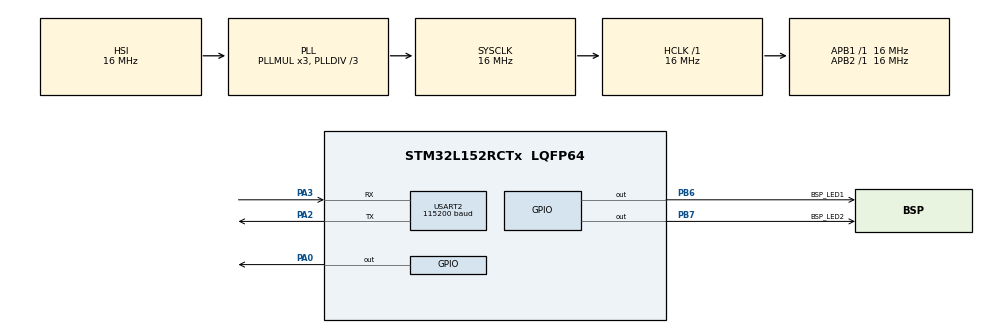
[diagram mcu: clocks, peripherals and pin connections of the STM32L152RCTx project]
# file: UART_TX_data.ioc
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Dma.Request0=USART2_TX
Dma.Request1=USART2_RX
Dma.USART2_RX.1.Direction=DMA_PERIPH_TO_MEMORY
Dma.USART2_RX.1.Instance=DMA1_Channel6
Dma.USART2_RX.1.MemDataAlignment=DMA_MDATAALIGN_BYTE
Dma.USART2_RX.1.MemInc=DMA_MINC_ENABLE
Dma.USART2_RX.1.Mode=DMA_NORMAL
Dma.USART2_RX.1.PeriphDataAlignment=DMA_PDATAALIGN_BYTE
Dma.USART2_RX.1.PeriphInc=DMA_PINC_DISABLE
Dma.USART2_RX.1.Priority=DMA_PRIORITY_LOW
Dma.USART2_TX.0.Direction=DMA_MEMORY_TO_PERIPH
Dma.USART2_TX.0.Instance=DMA1_Channel7
Dma.USART2_TX.0.MemDataAlignment=DMA_MDATAALIGN_BYTE
Dma.USART2_TX.0.MemInc=DMA_MINC_ENABLE
Dma.USART2_TX.0.Mode=DMA_CIRCULAR
Dma.USART2_TX.0.PeriphDataAlignment=DMA_PDATAALIGN_BYTE
Dma.USART2_TX.0.PeriphInc=DMA_PINC_DISABLE
Dma.USART2_TX.0.Priority=DMA_PRIORITY_LOW
Mcu.Family=STM32L1
Mcu.Name=STM32L152RCTx
Mcu.Package=LQFP64
NVIC.DMA1_Channel6_IRQn=true\:0\:0\:false\:false\:true\:false\:true\:true
NVIC.DMA1_Channel7_IRQn=true\:0\:0\:false\:false\:true\:false\:true\:true
NVIC.PriorityGroup=NVIC_PRIORITYGROUP_0
NVIC.USART2_IRQn=true\:0\:0\:false\:false\:true\:true\:true\:true
PA0-WKUP1.Signal=GPIO_Output
PA2.Mode=Asynchronous
PA2.Signal=USART2_TX
PA3.Mode=Asynchronous
PA3.Signal=USART2_RX
PB6.GPIO_Label=BSP_LED1
PB6.Signal=GPIO_Output
PB7.GPIO_Label=BSP_LED2
PB7.Signal=GPIO_Output
PH0-OSC_IN.Mode=HSE-External-Oscillator
PH0-OSC_IN.Signal=RCC_OSC_IN
PH1-OSC_OUT.Mode=HSE-External-Oscillator
PH1-OSC_OUT.Signal=RCC_OSC_OUT
ProjectManager.HeapSize=0x200
ProjectManager.StackSize=0x400
ProjectManager.TargetToolchain=STM32CubeIDE
RCC.48MHZClocksFreq_Value=24000000
RCC.AHBFreq_Value=16000000
RCC.APB1Freq_Value=16000000
RCC.APB1TimFreq_Value=16000000
RCC.APB2Freq_Value=16000000
RCC.APB2TimFreq_Value=16000000
RCC.HCLKFreq_Value=16000000
RCC.HSE_VALUE=8000000
RCC.HSI_VALUE=16000000
RCC.LSE_VALUE=32768
RCC.MSI_VALUE=2097000
RCC.PLLDIV=RCC_PLL_DIV3
RCC.RTCClockSelectionVirtual=RCC_RTCCLKSOURCE_LSE
RCC.SYSCLKFreq_VALUE=16000000
RCC.SYSCLKSource=RCC_SYSCLKSOURCE_PLLCLK
RCC.USBOutput=48000000
RCC.VCOOutputFreq_Value=48000000
USART2.BaudRate=115200
USART2.VirtualMode=VM_ASYNC
board=STM32L152C-DISCO

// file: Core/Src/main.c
/* USER CODE BEGIN Header */
/**
 ******************************************************************************
 * @file           : main.c
 * @brief          : Main program body
 ******************************************************************************
 * @attention
 *
 * Copyright (c) 2023 STMicroelectronics.
 * All rights reserved.
 *
 * This software is licensed under terms that can be found in the LICENSE file
 * in the root directory of this software component.
 * If no LICENSE file comes with this software, it is provided AS-IS.
 *
 ******************************************************************************
 */
/* USER CODE END Header */
#include "main.h"

UART_HandleTypeDef huart2;
DMA_HandleTypeDef hdma_usart2_tx;
DMA_HandleTypeDef hdma_usart2_rx;

void SystemClock_Config(void);
static void MX_GPIO_Init(void);
static void MX_DMA_Init(void);
static void MX_USART2_UART_Init(void);
/* USER CODE BEGIN PFP */
unsigned char data[] = "HIREnjadav\n\r";
unsigned char rx_data[20];

//void HAL_UART_TxHalfCpltCallback(UART_HandleTypeDef *huart) {
//	HAL_GPIO_TogglePin(BSP_LED1_GPIO_Port, BSP_LED1_Pin);
//
//}
//
//void HAL_UART_TxCpltCallback(UART_HandleTypeDef *huart) {
//	HAL_UART_Transmit_DMA(&huart2, data, 5);
//
//}

//void HAL_UART_RxCpltCallback(UART_HandleTypeDef *huart)
//{
//	HAL_UART_Receive_IT(&huart2, rx_data, 10);
//
//}
/* USER CODE END PFP */

int main(void) {

	/* MCU Configuration--------------------------------------------------------*/

	/* Reset of all peripherals, Initializes the Flash interface and the Systick. */
	HAL_Init();

	/* Configure the system clock */
	SystemClock_Config();

	/* Initialize all configured peripherals */
	MX_GPIO_Init();
	MX_DMA_Init();
	MX_USART2_UART_Init();
	/* USER CODE BEGIN 2 */

//HAL_UART_Receive_IT(&huart2, rx_data, 10);
//HAL_UART_Transmit_IT(&huart2, data, 5);
//HAL_UART_Receive_DMA(&huart2, rx_data, 5);
//	HAL_UART_Transmit_DMA(&huart2, data, 5);
	/* USER CODE END 2 */

	/* Infinite loop */
	while (1) {

		/* USER CODE BEGIN 3 */

		HAL_UART_Transmit(&huart2, data, 10, 1000);// poll method transmit data
//		HAL_Delay(500);

//
//		if (HAL_UART_Receive(&huart2, rx_data, 10, 1000) == HAL_OK) //read the data  poll method
//				{
//			HAL_GPIO_TogglePin(BSP_LED1_GPIO_Port, BSP_LED1_Pin);
//			HAL_UART_Transmit(&huart2, rx_data, 10, 1000);
//		}

	}
	/* USER CODE END 3 */
}

void SystemClock_Config(void) {
	RCC_OscInitTypeDef RCC_OscInitStruct = { 0 };
	RCC_ClkInitTypeDef RCC_ClkInitStruct = { 0 };

	/** Configure the main internal regulator output voltage
	 */
	__HAL_PWR_VOLTAGESCALING_CONFIG(PWR_REGULATOR_VOLTAGE_SCALE1);

	/** Initializes the RCC Oscillators according to the specified parameters
	 * in the RCC_OscInitTypeDef structure.
	 */
	RCC_OscInitStruct.OscillatorType = RCC_OSCILLATORTYPE_HSI;
	RCC_OscInitStruct.HSIState = RCC_HSI_ON;
	RCC_OscInitStruct.HSICalibrationValue = RCC_HSICALIBRATION_DEFAULT;
	RCC_OscInitStruct.PLL.PLLState = RCC_PLL_ON;
	RCC_OscInitStruct.PLL.PLLSource = RCC_PLLSOURCE_HSI;
	RCC_OscInitStruct.PLL.PLLMUL = RCC_PLL_MUL3;
	RCC_OscInitStruct.PLL.PLLDIV = RCC_PLL_DIV3;
	if (HAL_RCC_OscConfig(&RCC_OscInitStruct) != HAL_OK) {
		Error_Handler();
	}

	/** Initializes the CPU, AHB and APB buses clocks
	 */
	RCC_ClkInitStruct.ClockType = RCC_CLOCKTYPE_HCLK | RCC_CLOCKTYPE_SYSCLK
			| RCC_CLOCKTYPE_PCLK1 | RCC_CLOCKTYPE_PCLK2;
	RCC_ClkInitStruct.SYSCLKSource = RCC_SYSCLKSOURCE_PLLCLK;
	RCC_ClkInitStruct.AHBCLKDivider = RCC_SYSCLK_DIV1;
	RCC_ClkInitStruct.APB1CLKDivider = RCC_HCLK_DIV1;
	RCC_ClkInitStruct.APB2CLKDivider = RCC_HCLK_DIV1;

	if (HAL_RCC_ClockConfig(&RCC_ClkInitStruct, FLASH_LATENCY_0) != HAL_OK) {
		Error_Handler();
	}
}

static void MX_USART2_UART_Init(void) {

	huart2.Instance = USART2;
	huart2.Init.BaudRate = 115200;
	huart2.Init.WordLength = UART_WORDLENGTH_8B;
	huart2.Init.StopBits = UART_STOPBITS_1;
	huart2.Init.Parity = UART_PARITY_NONE;
	huart2.Init.Mode = UART_MODE_TX_RX;
	huart2.Init.HwFlowCtl = UART_HWCONTROL_NONE;
	huart2.Init.OverSampling = UART_OVERSAMPLING_16;
	if (HAL_UART_Init(&huart2) != HAL_OK) {
		Error_Handler();
	}

}

static void MX_DMA_Init(void) {

	/* DMA controller clock enable */
	__HAL_RCC_DMA1_CLK_ENABLE();

	/* DMA interrupt init */
	/* DMA1_Channel6_IRQn interrupt configuration */
	HAL_NVIC_SetPriority(DMA1_Channel6_IRQn, 0, 0);
	HAL_NVIC_EnableIRQ(DMA1_Channel6_IRQn);
	/* DMA1_Channel7_IRQn interrupt configuration */
	HAL_NVIC_SetPriority(DMA1_Channel7_IRQn, 0, 0);
	HAL_NVIC_EnableIRQ(DMA1_Channel7_IRQn);

}

static void MX_GPIO_Init(void) {
	GPIO_InitTypeDef GPIO_InitStruct = { 0 };

	/* GPIO Ports Clock Enable */
	__HAL_RCC_GPIOH_CLK_ENABLE();
	__HAL_RCC_GPIOA_CLK_ENABLE();
	__HAL_RCC_GPIOB_CLK_ENABLE();

	/*Configure GPIO pin Output Level */
	HAL_GPIO_WritePin(GPIOA, GPIO_PIN_0, GPIO_PIN_RESET);

	/*Configure GPIO pin Output Level */
	HAL_GPIO_WritePin(GPIOB, BSP_LED1_Pin | BSP_LED2_Pin, GPIO_PIN_RESET);

	/*Configure GPIO pin : PA0 */
	GPIO_InitStruct.Pin = GPIO_PIN_0;
	GPIO_InitStruct.Mode = GPIO_MODE_OUTPUT_PP;
	GPIO_InitStruct.Pull = GPIO_NOPULL;
	GPIO_InitStruct.Speed = GPIO_SPEED_FREQ_LOW;
	HAL_GPIO_Init(GPIOA, &GPIO_InitStruct);

	/*Configure GPIO pins : BSP_LED1_Pin BSP_LED2_Pin */
	GPIO_InitStruct.Pin = BSP_LED1_Pin | BSP_LED2_Pin;
	GPIO_InitStruct.Mode = GPIO_MODE_OUTPUT_PP;
	GPIO_InitStruct.Pull = GPIO_NOPULL;
	GPIO_InitStruct.Speed = GPIO_SPEED_FREQ_LOW;
	HAL_GPIO_Init(GPIOB, &GPIO_InitStruct);

}

void Error_Handler(void) {
	__disable_irq();
	while (1) {
	}
}
